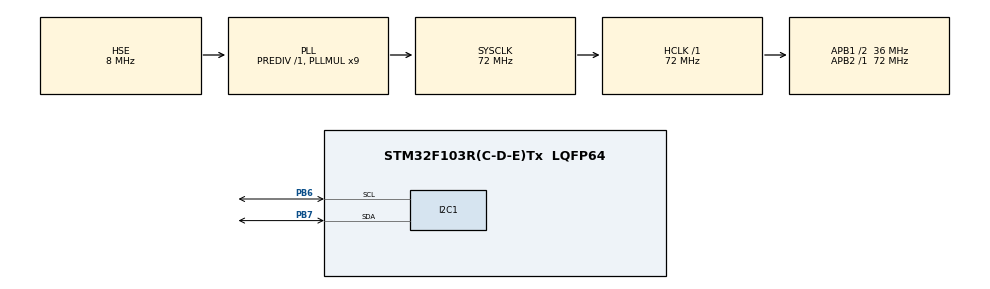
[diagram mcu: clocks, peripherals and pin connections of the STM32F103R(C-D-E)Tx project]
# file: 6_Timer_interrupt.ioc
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FREERTOS.Tasks01=Timer_int,24,256,interrupt_entry,Default,NULL,Dynamic,NULL,NULL
I2C1.I2C_Mode=I2C_Fast
Mcu.Family=STM32F1
Mcu.Name=STM32F103R(C-D-E)Tx
Mcu.Package=LQFP64
NVIC.PriorityGroup=NVIC_PRIORITYGROUP_4
NVIC.TIM6_IRQn=true\:5\:0\:false\:false\:true\:true\:true\:true\:true
NVIC.TIM7_IRQn=true\:15\:0\:false\:false\:true\:false\:false\:true\:true
NVIC.TimeBase=TIM7_IRQn
NVIC.TimeBaseIP=TIM7
PA13.Mode=Serial_Wire
PA13.Signal=SYS_JTMS-SWDIO
PA14.Mode=Serial_Wire
PA14.Signal=SYS_JTCK-SWCLK
PB6.Mode=I2C
PB6.Signal=I2C1_SCL
PB7.Mode=I2C
PB7.Signal=I2C1_SDA
PC14-OSC32_IN.Mode=LSE-External-Oscillator
PC14-OSC32_IN.Signal=RCC_OSC32_IN
PC15-OSC32_OUT.Mode=LSE-External-Oscillator
PC15-OSC32_OUT.Signal=RCC_OSC32_OUT
PD0-OSC_IN.Mode=HSE-External-Oscillator
PD0-OSC_IN.Signal=RCC_OSC_IN
PD1-OSC_OUT.Mode=HSE-External-Oscillator
PD1-OSC_OUT.Signal=RCC_OSC_OUT
ProjectManager.HeapSize=0x200
ProjectManager.StackSize=0x400
ProjectManager.TargetToolchain=MDK-ARM V5.32
RCC.AHBFreq_Value=72000000
RCC.APB1CLKDivider=RCC_HCLK_DIV2
RCC.APB1Freq_Value=36000000
RCC.APB1TimFreq_Value=72000000
RCC.APB2Freq_Value=72000000
RCC.APB2TimFreq_Value=72000000
RCC.HCLKFreq_Value=72000000
RCC.PLLMUL=RCC_PLL_MUL9
RCC.PLLSourceVirtual=RCC_PLLSOURCE_HSE
RCC.SYSCLKFreq_VALUE=72000000
RCC.SYSCLKSource=RCC_SYSCLKSOURCE_PLLCLK
RCC.USBFreq_Value=72000000
TIM6.Period=10000-1
TIM6.Prescaler=7200-1
VP_FREERTOS_VS_CMSIS_V2.Mode=CMSIS_V2
VP_SYS_VS_tim7.Mode=TIM7
VP_TIM6_VS_ClockSourceINT.Mode=Enable_Timer
board=custom

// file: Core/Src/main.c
/* USER CODE BEGIN Header */
/**
  ******************************************************************************
  * @file           : main.c
  * @brief          : Main program body
  ******************************************************************************
  * @attention
  *
  * Copyright (c) 2024 STMicroelectronics.
  * All rights reserved.
  *
  * This software is licensed under terms that can be found in the LICENSE file
  * in the root directory of this software component.
  * If no LICENSE file comes with this software, it is provided AS-IS.
  *
  ******************************************************************************
  */
/* USER CODE END Header */
#include "main.h"
#include "cmsis_os.h"
#include "i2c.h"
#include "tim.h"
#include "gpio.h"

/* USER CODE BEGIN PV */
uint16_t Num = 0;
/* USER CODE END PV */

void SystemClock_Config(void);
void MX_FREERTOS_Init(void);

int main(void)
{

  /* MCU Configuration--------------------------------------------------------*/

  /* Reset of all peripherals, Initializes the Flash interface and the Systick. */
  HAL_Init();

  /* Configure the system clock */
  SystemClock_Config();

  /* Initialize all configured peripherals */
  MX_GPIO_Init();
  MX_I2C1_Init();
  MX_TIM6_Init();

  /* Init scheduler */
  osKernelInitialize();

  /* Call init function for freertos objects (in freertos.c) */
  MX_FREERTOS_Init();

  /* Start scheduler */
  osKernelStart();

  /* We should never get here as control is now taken by the scheduler */
  /* Infinite loop */
  while (1)
  {

  }
}

void SystemClock_Config(void)
{
  RCC_OscInitTypeDef RCC_OscInitStruct = {0};
  RCC_ClkInitTypeDef RCC_ClkInitStruct = {0};

  /** Initializes the RCC Oscillators according to the specified parameters
  * in the RCC_OscInitTypeDef structure.
  */
  RCC_OscInitStruct.OscillatorType = RCC_OSCILLATORTYPE_HSE;
  RCC_OscInitStruct.HSEState = RCC_HSE_ON;
  RCC_OscInitStruct.HSEPredivValue = RCC_HSE_PREDIV_DIV1;
  RCC_OscInitStruct.HSIState = RCC_HSI_ON;
  RCC_OscInitStruct.PLL.PLLState = RCC_PLL_ON;
  RCC_OscInitStruct.PLL.PLLSource = RCC_PLLSOURCE_HSE;
  RCC_OscInitStruct.PLL.PLLMUL = RCC_PLL_MUL9;
  if (HAL_RCC_OscConfig(&RCC_OscInitStruct) != HAL_OK)
  {
    Error_Handler();
  }

  /** Initializes the CPU, AHB and APB buses clocks
  */
  RCC_ClkInitStruct.ClockType = RCC_CLOCKTYPE_HCLK|RCC_CLOCKTYPE_SYSCLK
                              |RCC_CLOCKTYPE_PCLK1|RCC_CLOCKTYPE_PCLK2;
  RCC_ClkInitStruct.SYSCLKSource = RCC_SYSCLKSOURCE_PLLCLK;
  RCC_ClkInitStruct.AHBCLKDivider = RCC_SYSCLK_DIV1;
  RCC_ClkInitStruct.APB1CLKDivider = RCC_HCLK_DIV2;
  RCC_ClkInitStruct.APB2CLKDivider = RCC_HCLK_DIV1;

  if (HAL_RCC_ClockConfig(&RCC_ClkInitStruct, FLASH_LATENCY_2) != HAL_OK)
  {
    Error_Handler();
  }
}

void HAL_TIM_PeriodElapsedCallback(TIM_HandleTypeDef *htim)
{
  if (htim->Instance == TIM7) {
    HAL_IncTick();
  }
  /* USER CODE BEGIN Callback 1 */
  if (htim->Instance == TIM6) {
    Num++;
  }
  /* USER CODE END Callback 1 */
}

void Error_Handler(void)
{
  __disable_irq();
  while (1)
  {
  }
}

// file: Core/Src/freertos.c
/* USER CODE BEGIN Header */
/**
  ******************************************************************************
  * File Name          : freertos.c
  * Description        : Code for freertos applications
  ******************************************************************************
  * @attention
  *
  * Copyright (c) 2024 STMicroelectronics.
  * All rights reserved.
  *
  * This software is licensed under terms that can be found in the LICENSE file
  * in the root directory of this software component.
  * If no LICENSE file comes with this software, it is provided AS-IS.
  *
  ******************************************************************************
  */
/* USER CODE END Header */

#include "FreeRTOS.h"
#include "task.h"
#include "main.h"
#include "cmsis_os.h"

/* USER CODE BEGIN Includes */
#include "oled.h"
#include "tim.h"
/* USER CODE END Includes */

/* Definitions for Timer_int */
osThreadId_t Timer_intHandle;
const osThreadAttr_t Timer_int_attributes = {
  .name = "Timer_int",
  .stack_size = 256 * 4,
  .priority = (osPriority_t) osPriorityNormal,
};

void interrupt_entry(void *argument);

void MX_FREERTOS_Init(void); /* (MISRA C 2004 rule 8.1) */

void MX_FREERTOS_Init(void) {

  /* Create the thread(s) */
  /* creation of Timer_int */
  Timer_intHandle = osThreadNew(interrupt_entry, NULL, &Timer_int_attributes);

}

void interrupt_entry(void *argument)
{
  /* USER CODE BEGIN interrupt_entry */
  uint16_t timer_count = 0;
  OLED_Init();
  OLED_Clear();
  OLED_ShowString(0,0,"Num:",16,0);
  OLED_ShowString(0,2,"Cnt:",16,0);
  HAL_TIM_Base_Start_IT(&htim6);
  /* Infinite loop */
  for(;;)
  {
    timer_count = __HAL_TIM_GET_COUNTER(&htim6);
    OLED_ShowNum(30,0,Num,5,16,0);
    OLED_ShowNum(30,2,timer_count,5,16,0);
    osDelay(1);
  }
  /* USER CODE END interrupt_entry */
}
